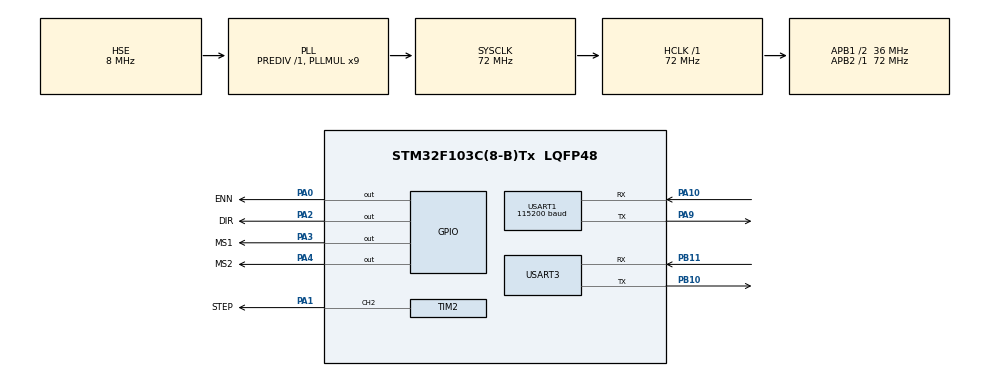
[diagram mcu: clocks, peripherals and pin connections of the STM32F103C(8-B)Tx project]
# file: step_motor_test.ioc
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Dma.Request0=USART1_TX
Dma.USART1_TX.0.Direction=DMA_MEMORY_TO_PERIPH
Dma.USART1_TX.0.Instance=DMA1_Channel4
Dma.USART1_TX.0.MemDataAlignment=DMA_MDATAALIGN_BYTE
Dma.USART1_TX.0.MemInc=DMA_MINC_ENABLE
Dma.USART1_TX.0.Mode=DMA_NORMAL
Dma.USART1_TX.0.PeriphDataAlignment=DMA_PDATAALIGN_BYTE
Dma.USART1_TX.0.PeriphInc=DMA_PINC_DISABLE
Dma.USART1_TX.0.Priority=DMA_PRIORITY_MEDIUM
Mcu.Family=STM32F1
Mcu.Name=STM32F103C(8-B)Tx
Mcu.Package=LQFP48
NVIC.DMA1_Channel4_IRQn=true\:0\:0\:false\:false\:true\:false\:true\:true
NVIC.PriorityGroup=NVIC_PRIORITYGROUP_4
NVIC.TIM2_IRQn=true\:1\:0\:true\:false\:true\:true\:true\:true
NVIC.TIM3_IRQn=true\:2\:0\:true\:false\:true\:true\:true\:true
NVIC.USART1_IRQn=true\:3\:0\:true\:false\:true\:true\:true\:true
PA0-WKUP.GPIO_Label=ENN
PA0-WKUP.PinState=GPIO_PIN_SET
PA0-WKUP.Signal=GPIO_Output
PA1.GPIO_Label=STEP
PA1.Signal=S_TIM2_CH2
PA10.Mode=Asynchronous
PA10.Signal=USART1_RX
PA13.Mode=Serial_Wire
PA13.Signal=SYS_JTMS-SWDIO
PA14.Mode=Serial_Wire
PA14.Signal=SYS_JTCK-SWCLK
PA2.GPIO_Label=DIR
PA2.Signal=GPIO_Output
PA3.GPIO_Label=MS1
PA3.Signal=GPIO_Output
PA4.GPIO_Label=MS2
PA4.Signal=GPIO_Output
PA9.Mode=Asynchronous
PA9.Signal=USART1_TX
PB10.Mode=Asynchronous
PB10.Signal=USART3_TX
PB11.Mode=Asynchronous
PB11.Signal=USART3_RX
PD0-OSC_IN.Mode=HSE-External-Oscillator
PD0-OSC_IN.Signal=RCC_OSC_IN
PD1-OSC_OUT.Mode=HSE-External-Oscillator
PD1-OSC_OUT.Signal=RCC_OSC_OUT
ProjectManager.HeapSize=0x200
ProjectManager.StackSize=0x400
ProjectManager.TargetToolchain=MDK-ARM V5
RCC.AHBFreq_Value=72000000
RCC.APB1CLKDivider=RCC_HCLK_DIV2
RCC.APB1Freq_Value=36000000
RCC.APB1TimFreq_Value=72000000
RCC.APB2Freq_Value=72000000
RCC.APB2TimFreq_Value=72000000
RCC.HCLKFreq_Value=72000000
RCC.PLLMUL=RCC_PLL_MUL9
RCC.PLLSourceVirtual=RCC_PLLSOURCE_HSE
RCC.SYSCLKFreq_VALUE=72000000
RCC.SYSCLKSource=RCC_SYSCLKSOURCE_PLLCLK
RCC.USBFreq_Value=72000000
SH.S_TIM2_CH2.0=TIM2_CH2,PWM Generation2 CH2
TIM2.AutoReloadPreload=TIM_AUTORELOAD_PRELOAD_ENABLE
TIM2.Channel-PWM\ Generation2\ CH2=TIM_CHANNEL_2
TIM2.Period=8999
TIM2.Prescaler=99
TIM2.Pulse-PWM\ Generation2\ CH2=4500
TIM2.TIM_MasterOutputTrigger=TIM_TRGO_UPDATE
TIM2.TIM_MasterSlaveMode=TIM_MASTERSLAVEMODE_ENABLE
TIM3.Period=1000
TIM3.Prescaler=71
TIM3.TIM_MasterSlaveMode=TIM_MASTERSLAVEMODE_ENABLE
USART1.BaudRate=115200
USART1.VirtualMode=VM_ASYNC
USART3.VirtualMode=VM_ASYNC
VP_TIM2_VS_ClockSourceINT.Mode=Internal
VP_TIM3_VS_ClockSourceINT.Mode=Internal
board=custom

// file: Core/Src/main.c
/* USER CODE BEGIN Header */
/**
  ******************************************************************************
  * @file           : main.c
  * @brief          : Main program body
  ******************************************************************************
  * @attention
  *
  * Copyright (c) 2026 STMicroelectronics.
  * All rights reserved.
  *
  * This software is licensed under terms that can be found in the LICENSE file
  * in the root directory of this software component.
  * If no LICENSE file comes with this software, it is provided AS-IS.
  *
  ******************************************************************************
  */
/* USER CODE END Header */
#include "main.h"
#include "dma.h"
#include "tim.h"
#include "usart.h"
#include "gpio.h"

/* USER CODE BEGIN Includes */

#include "step_motor_contorl_hardware.h"
#include "uart_control.h"

/* USER CODE END Includes */

void SystemClock_Config(void);

int main(void)
{

  /* MCU Configuration--------------------------------------------------------*/

  /* Reset of all peripherals, Initializes the Flash interface and the Systick. */
  HAL_Init();

  /* Configure the system clock */
  SystemClock_Config();

  /* Initialize all configured peripherals */
  MX_GPIO_Init();
  MX_DMA_Init();
  MX_TIM2_Init();
  MX_TIM3_Init();
  MX_USART1_UART_Init();
  MX_USART3_UART_Init();
  /* USER CODE BEGIN 2 */

  /* ① UART 控制初始化：USART1 波特率→115200，TMC2209 先读寄存器快照再写入配置 */
  UART_Control_Init();

  /* ② 使能电机（UART 控制方式下不自动启动，等待上位机 START 指令） */
  Motor_Init();

  /* USER CODE END 2 */

  /* Infinite loop */
  while (1)
  {

    /* USER CODE BEGIN 3 */

    /* UART 控制轮询：解析上位机指令（START/STOP/STATUS/HELP） */
    UART_Control_Task();

  }
  /* USER CODE END 3 */
}

void SystemClock_Config(void)
{
  RCC_OscInitTypeDef RCC_OscInitStruct = {0};
  RCC_ClkInitTypeDef RCC_ClkInitStruct = {0};

  /** Initializes the RCC Oscillators according to the specified parameters
  * in the RCC_OscInitTypeDef structure.
  */
  RCC_OscInitStruct.OscillatorType = RCC_OSCILLATORTYPE_HSE;
  RCC_OscInitStruct.HSEState = RCC_HSE_ON;
  RCC_OscInitStruct.HSEPredivValue = RCC_HSE_PREDIV_DIV1;
  RCC_OscInitStruct.HSIState = RCC_HSI_ON;
  RCC_OscInitStruct.PLL.PLLState = RCC_PLL_ON;
  RCC_OscInitStruct.PLL.PLLSource = RCC_PLLSOURCE_HSE;
  RCC_OscInitStruct.PLL.PLLMUL = RCC_PLL_MUL9;
  if (HAL_RCC_OscConfig(&RCC_OscInitStruct) != HAL_OK)
  {
    Error_Handler();
  }

  /** Initializes the CPU, AHB and APB buses clocks
  */
  RCC_ClkInitStruct.ClockType = RCC_CLOCKTYPE_HCLK|RCC_CLOCKTYPE_SYSCLK
                              |RCC_CLOCKTYPE_PCLK1|RCC_CLOCKTYPE_PCLK2;
  RCC_ClkInitStruct.SYSCLKSource = RCC_SYSCLKSOURCE_PLLCLK;
  RCC_ClkInitStruct.AHBCLKDivider = RCC_SYSCLK_DIV1;
  RCC_ClkInitStruct.APB1CLKDivider = RCC_HCLK_DIV2;
  RCC_ClkInitStruct.APB2CLKDivider = RCC_HCLK_DIV1;

  if (HAL_RCC_ClockConfig(&RCC_ClkInitStruct, FLASH_LATENCY_2) != HAL_OK)
  {
    Error_Handler();
  }
}

void Error_Handler(void)
{
  __disable_irq();
  while (1)
  {
  }
}
